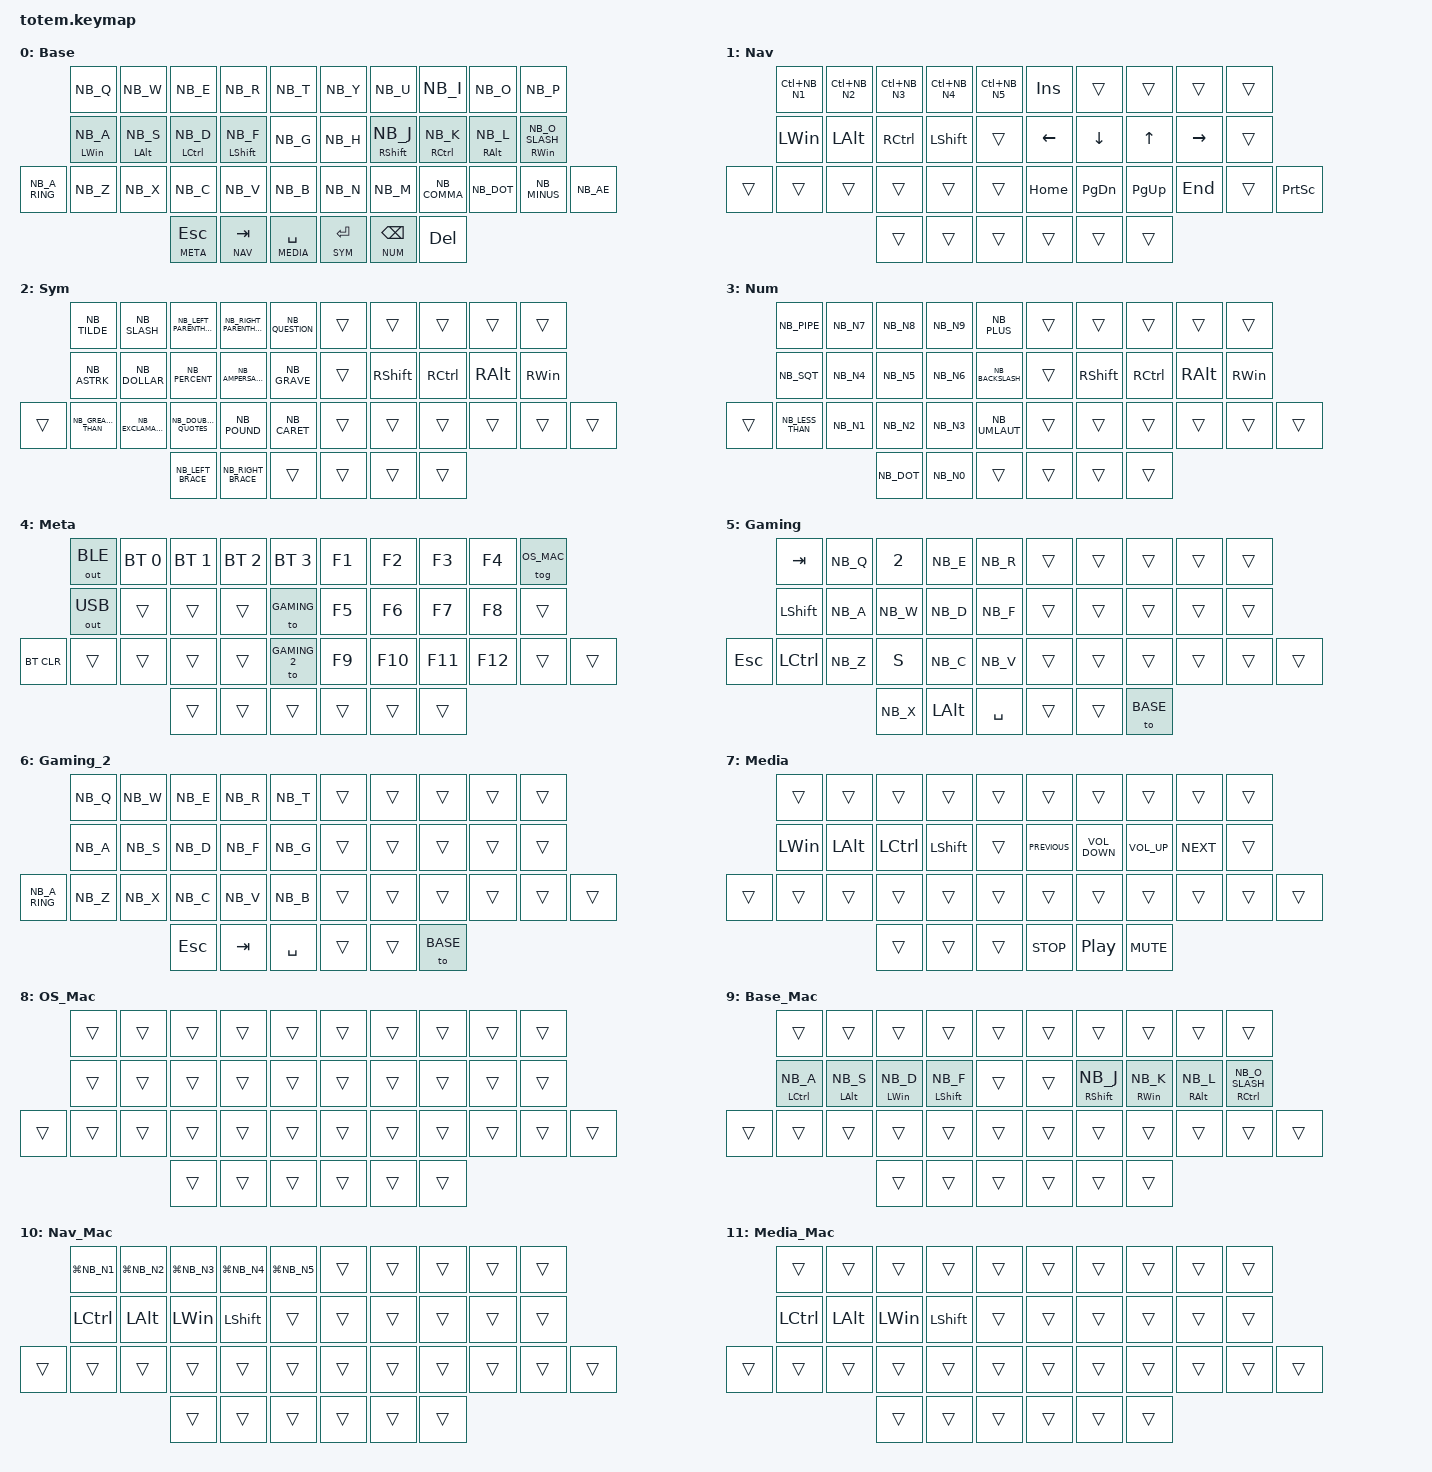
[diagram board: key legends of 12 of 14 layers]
//
//                                                        ▀▀▀▀▀     ▀▀▀▀▀          ▀▀█▀▀
//                                                        ▄▀▀▀▄  ▄  ▄▀▀▀▄  ▄  ▄▀▀▀▄  █  ▄▀▀▀▄
//                                                        █   █  █  █   █  █  █   █  █  █   █
//                                                         ▀▀▀   █   ▀▀▀   █   ▀▀▀   ▀   ▀▀▀
//                                                               █      ▄▄▄█▄▄▄    █   █  
//                                                               ▀      █  █  █     █▄█
//                                                             ▀▀▀▀▀    █  █  █      ▀
//                                                                      ▀  ▀  ▀
//
// ▄▄▄▄▄▄▄▄▄▄▄▄▄▄▄▄▄▄▄▄▄▄▄▄▄▄▄▄▄▄▄▄▄▄▄▄▄▄▄▄▄▄▄▄▄▄▄▄▄▄▄▄▄▄▄▄▄▄▄▄▄▄▄▄▄▄▄▄▄▄▄▄▄▄▄▄▄▄▄▄▄▄▄▄▄▄▄▄▄▄▄▄▄▄▄▄▄▄▄▄▄▄▄▄▄▄▄▄▄▄▄▄▄▄▄▄▄▄▄▄▄▄▄▄▄▄▄▄▄▄▄▄▄▄▄▄▄▄▄▄▄▄▄▄▄▄▄▄▄

#include "keys_nb.h"
#include <behaviors.dtsi>
#include <dt-bindings/zmk/bt.h>
#include <dt-bindings/zmk/keys.h>
#include <dt-bindings/zmk/outputs.h>

#define BASE        0
#define NAV         1
#define SYM         2
#define NUM         3
#define META        4
#define GAMING      5
#define GAMING_2    6
#define MEDIA       7
#define OS_MAC      8
#define BASE_MAC    9
#define NAV_MAC     10
#define MEDIA_MAC   11
#define NUM_MAC     12
#define SYM_MAC     13

&mt {
    quick-tap-ms = <100>;
    flavor = "tap-preferred";
    tapping-term-ms = <170>;
};

&lt {
    tapping-term-ms = <240>;
    flavor = "balanced";
    quick-tap-ms = <150>;
};

/ {
    behaviors {
        hm: homerow_mods {
            compatible = "zmk,behavior-hold-tap";
            #binding-cells = <2>;
            flavor = "tap-preferred";
            tapping-term-ms = <250>;
            quick-tap-ms = <125>;
            bindings = <&kp>, <&kp>;
        };

        cw: CapsWord {
            compatible = "zmk,behavior-caps-word";
            #binding-cells = <0>;
            continue-list = <BACKSPACE UNDERSCORE DELETE ENTER SPACE>;
        };

    };

    combos {
        compatible = "zmk,combos";

        CapsWord {
            bindings = <&caps_word>;
            key-positions = <13 16>;
        };
    };

    keymap {
        compatible = "zmk,keymap";

        Base {
            display-name = "Base";
            bindings = <
               &kp NB_Q           &kp NB_W       &kp NB_E        &kp NB_R         &kp NB_T       &kp NB_Y     &kp NB_U        &kp NB_I        &kp NB_O       &kp NB_P
               &hm LEFT_WIN NB_A  &hm LALT NB_S  &hm LCTRL NB_D  &hm LSHIFT NB_F  &kp NB_G       &kp NB_H     &hm RSHFT NB_J  &hm RCTRL NB_K  &hm RALT NB_L  &hm RIGHT_WIN NB_O_SLASH
&kp NB_A_RING  &kp NB_Z           &kp NB_X       &kp NB_C        &kp NB_V         &kp NB_B       &kp NB_N     &kp NB_M        &kp NB_COMMA    &kp NB_DOT     &kp NB_MINUS              &kp NB_AE
                                                 &lt META ESC      &lt NAV TAB      &lt MEDIA SPACE  &lt SYM ENTER   &lt NUM BSPC    &kp DELETE
            >;
        };

        Nav {
            display-name = "Nav";
            bindings = <
        &kp LC(NB_N1)  &kp LC(NB_N2) &kp LC(NB_N3)  &kp LC(NB_N4)   &kp LC(NB_N5)    &kp INSERT      &trans          &trans        &trans           &trans
        &kp LEFT_WIN   &kp LEFT_ALT  &kp RCTRL      &kp LEFT_SHIFT  &trans           &kp LEFT_ARROW  &kp DOWN_ARROW  &kp UP_ARROW  &kp RIGHT_ARROW  &trans
&trans  &trans         &trans        &trans         &trans          &trans           &kp HOME        &kp PAGE_DOWN   &kp PG_UP     &kp END          &trans  &kp PRINTSCREEN
                                     &trans         &trans          &trans           &trans          &trans          &trans
            >;
        };

        Sym {
            display-name = "Sym";
            bindings = <
        &kp NB_TILDE         &kp NB_SLASH        &kp NB_LEFT_PARENTHESIS  &kp NB_RIGHT_PARENTHESIS  &kp NB_QUESTION    &trans  &trans           &trans     &trans         &trans
        &kp NB_ASTRK         &kp NB_DOLLAR       &kp NB_PERCENT           &kp NB_AMPERSAND          &kp NB_GRAVE       &trans  &kp RIGHT_SHIFT  &kp RCTRL  &kp RIGHT_ALT  &kp RIGHT_WIN
&trans  &kp NB_GREATER_THAN  &kp NB_EXCLAMATION  &kp NB_DOUBLE_QUOTES     &kp NB_POUND              &kp NB_CARET       &trans  &trans           &trans     &trans         &trans         &trans
                                                 &kp NB_LEFT_BRACE        &kp NB_RIGHT_BRACE        &trans             &trans  &trans           &trans
            >;
        };

        Num {
            bindings = <
        &kp NB_PIPE       &kp NB_N7  &kp NB_N8   &kp NB_N9  &kp NB_PLUS         &trans  &trans           &trans     &trans         &trans
        &kp NB_SQT        &kp NB_N4  &kp NB_N5   &kp NB_N6  &kp NB_BACKSLASH    &trans  &kp RIGHT_SHIFT  &kp RCTRL  &kp RIGHT_ALT  &kp RIGHT_WIN
&trans  &kp NB_LESS_THAN  &kp NB_N1  &kp NB_N2   &kp NB_N3  &kp NB_UMLAUT       &trans  &trans           &trans     &trans         &trans         &trans
                                     &kp NB_DOT  &kp NB_N0  &trans              &trans  &trans           &trans
            >;

            display-name = "Num";
        };

        Meta {
            bindings = <
        &out OUT_BLE  &bt BT_SEL 0  &bt BT_SEL 1  &bt BT_SEL 2  &bt BT_SEL 3  &kp F1  &kp F2   &kp F3   &kp F4   &tog OS_MAC
        &out OUT_USB  &trans        &trans        &trans        &to GAMING         &kp F5  &kp F6   &kp F7   &kp F8   &trans
&bt BT_CLR  &trans  &trans  &trans  &trans  &to GAMING_2          &kp F9  &kp F10  &kp F11  &kp F12  &trans  &trans
                            &trans  &trans  &trans    &trans  &trans   &trans
            >;

            display-name = "Meta";
        };

        Gaming {
            bindings = <
            &kp TAB           &kp NB_Q  &kp NUMBER_2  &kp NB_E      &kp NB_R     &trans  &trans  &trans  &trans  &trans
            &kp LEFT_SHIFT    &kp NB_A  &kp NB_W      &kp NB_D      &kp NB_F     &trans  &trans  &trans  &trans  &trans
&kp ESCAPE  &kp LEFT_CONTROL  &kp NB_Z  &kp S         &kp NB_C      &kp NB_V     &trans  &trans  &trans  &trans  &trans  &trans
                                        &kp NB_X      &kp LEFT_ALT  &kp SPACE    &trans  &trans  &to BASE
            >;

            display-name = "Gaming";
        };

        Gaming_2 {
            display-name = "Gaming_2";
            bindings = <
               &kp NB_Q  &kp NB_W  &kp NB_E  &kp NB_R  &kp NB_T     &trans  &trans  &trans  &trans  &trans
               &kp NB_A  &kp NB_S  &kp NB_D  &kp NB_F  &kp NB_G     &trans  &trans  &trans  &trans  &trans
&kp NB_A_RING  &kp NB_Z  &kp NB_X  &kp NB_C  &kp NB_V  &kp NB_B     &trans  &trans  &trans  &trans  &trans  &trans
                                   &kp ESC   &kp TAB   &kp SPACE    &trans  &trans  &to BASE
            >;
        };

        Media {
            bindings = <
        &trans        &trans        &trans            &trans          &trans    &trans          &trans             &trans        &trans      &trans
        &kp LEFT_WIN  &kp LEFT_ALT  &kp LEFT_CONTROL  &kp LEFT_SHIFT  &trans    &kp C_PREVIOUS  &kp C_VOLUME_DOWN  &kp C_VOL_UP  &kp C_NEXT  &trans
&trans  &trans        &trans        &trans            &trans          &trans    &trans          &trans             &trans        &trans      &trans  &trans
                                    &trans            &trans          &trans    &kp C_STOP      &kp C_PP           &kp C_MUTE
            >;

            display-name = "Media";
        };

        os_mac {
            display-name = "OS_Mac";
            bindings = <
        &trans  &trans  &trans  &trans  &trans  &trans  &trans  &trans  &trans  &trans
        &trans  &trans  &trans  &trans  &trans  &trans  &trans  &trans  &trans  &trans
&trans  &trans  &trans  &trans  &trans  &trans  &trans  &trans  &trans  &trans  &trans  &trans
                                 &trans  &trans  &trans  &trans  &trans  &trans
            >;
        };

        base_mac {
            display-name = "Base_Mac";
            bindings = <
        &trans                &trans        &trans            &trans               &trans  &trans  &trans         &trans              &trans         &trans
        &hm LEFT_CONTROL NB_A &hm LALT NB_S &hm LEFT_WIN NB_D &hm LSHIFT NB_F      &trans  &trans  &hm RSHFT NB_J &hm RIGHT_WIN NB_K  &hm RALT NB_L  &hm RIGHT_CONTROL NB_O_SLASH
&trans  &trans                &trans        &trans            &trans               &trans  &trans  &trans         &trans              &trans         &trans  &trans
                                                   &trans      &trans               &trans  &trans  &trans         &trans
            >;
        };

        nav_mac {
            display-name = "Nav_Mac";
            bindings = <
        &kp LG(NB_N1)    &kp LG(NB_N2)  &kp LG(NB_N3)  &kp LG(NB_N4)  &kp LG(NB_N5)    &trans  &trans  &trans        &trans  &trans
        &kp LEFT_CONTROL &kp LEFT_ALT   &kp LEFT_WIN   &kp LEFT_SHIFT &trans           &trans  &trans  &trans        &trans  &trans
&trans  &trans           &trans         &trans         &trans         &trans           &trans  &trans  &trans        &trans  &trans  &trans
                                      &trans           &trans         &trans           &trans  &trans  &trans
            >;
        };

        media_mac {
            display-name = "Media_Mac";
            bindings = <
        &trans           &trans        &trans        &trans           &trans  &trans  &trans  &trans  &trans  &trans
        &kp LEFT_CONTROL &kp LEFT_ALT  &kp LEFT_WIN  &kp LEFT_SHIFT   &trans  &trans  &trans  &trans  &trans  &trans
&trans  &trans           &trans        &trans        &trans  &trans  &trans  &trans  &trans  &trans  &trans  &trans
                                &trans  &trans  &trans  &trans  &trans  &trans
            >;
        };

        num_mac {
            display-name = "Num_Mac";
            bindings = <
        &trans  &trans  &trans  &trans  &trans  &trans  &trans             &trans        &trans      &trans
        &trans  &trans  &trans  &trans  &trans  &trans  &kp RIGHT_SHIFT    &kp LEFT_WIN  &kp RALT    &kp RIGHT_CONTROL
&trans  &trans  &trans  &trans  &trans  &trans  &trans  &trans             &trans        &trans      &trans  &trans
                                  &trans  &trans  &trans  &trans             &trans        &trans
            >;
        };

        sym_mac {
            display-name = "Sym_Mac";
            bindings = <
        &trans  &trans  &trans  &trans  &trans  &trans  &trans             &trans        &trans      &trans
        &trans  &trans  &trans  &trans  &trans  &trans  &kp RIGHT_SHIFT    &kp LEFT_WIN  &kp RALT    &kp RIGHT_CONTROL
&trans  &trans  &trans  &trans  &trans  &trans  &trans  &trans             &trans        &trans      &trans  &trans
                                  &trans  &trans  &trans  &trans             &trans        &trans
            >;
        };
    };

    conditional_layers {
        compatible = "zmk,conditional-layers";

        base_mac_layer {
            if-layers = <OS_MAC>;
            then-layer = <BASE_MAC>;
        };

        nav_mac_layer {
            if-layers = <NAV OS_MAC>;
            then-layer = <NAV_MAC>;
        };

        media_mac_layer {
            if-layers = <MEDIA OS_MAC>;
            then-layer = <MEDIA_MAC>;
        };

        num_mac_layer {
            if-layers = <NUM OS_MAC>;
            then-layer = <NUM_MAC>;
        };

        sym_mac_layer {
            if-layers = <SYM OS_MAC>;
            then-layer = <SYM_MAC>;
        };
    };
};
